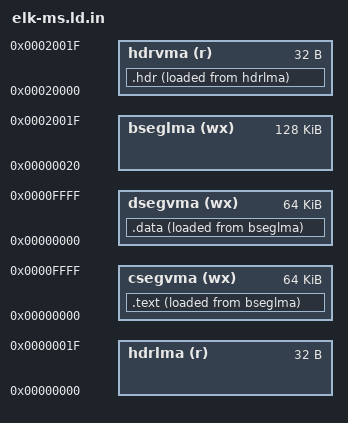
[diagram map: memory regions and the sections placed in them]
#!/bin/sh

set -e
cmd1='#'
cmd2='#'
w1=with
w2=with
case "$1" in
  -nostdlib)
    cmd1='/^@if_starts@/,/^@endif@/ d'
    cmd2='/^@if_libs@/,/^@endif@/ d'
    w1=without
    w2=without;;
  -nostartfiles)
     cmd1='/^@if_starts@/,/^@endif@/ d'
     w1=without;;
  -nodefaultlibs)
     cmd2='/^@if_libs@/,/^@endif@/ d'
     w2=without;;
esac
sed -e "$cmd1" -e "$cmd2" -e "s;@withstarts@;$w1;g" -e "s;@withlibs@;$w2;g" \
    -e "s/@self@/`basename "$0"`/g" -e "/^@if/ d" -e "/^@endif@/ d" <<'EOF'
/* Linker script for ELKS executables with separate data and text segments,
   @withstarts@ startup files, and @withlibs@ default libraries.  Generated
   from @self@.  */

OUTPUT_FORMAT(binary)
ENTRY(_start)
@if_starts@
INPUT(-l:crtbegin.o -l:crtend.o -l:elks-crt0.o)
@endif@
@if_libs@
GROUP(-lc -lgcc -lelks -lm)
@endif@
MEMORY
  {
    /* Place header VMA outside of program address space.  */
    hdrlma  (r)	 : ORIGIN = 0x00000, LENGTH = 32
    hdrvma  (r)  : ORIGIN = 0x20000, LENGTH = 32

    /* Account for the 32-byte header.  */
    bseglma (wx) : ORIGIN = 0x00020, LENGTH = 0x20000
    csegvma (wx) : ORIGIN = 0x00000, LENGTH = 0x10000
    dsegvma (wx) : ORIGIN = 0x00000, LENGTH = 0x10000
  }

SECTIONS
  {
    /* There's no binutils configuration which directly supports the ELKS
       binary format, but's it's easy to create the necessary header.  */
    .hdr : {
		LONG (0x04300301);	/* Magic.  */
		LONG (32);		/* Header length.  */
		LONG (__ltext_padded);
		LONG (__ldata);
		LONG (__lbss);
		LONG (_start);		/* Entry point.  */
		LONG (_total_adjusted);	/* Total memory allocated.  */
		LONG (0);
	} >hdrvma AT>hdrlma

    /* Target text sections.  */
    .text : {
		__stext = .;
		*(.startupA)
		*(.init)
		*(.startupB)
		*(.fini)
		*(.startupC)
		*(.text) *(.text.*)
		__etext = .;

		/* Work around linker bug.  The linker will 4-byte align the VMA
		 * without being asked to do so, but won't do the same for the
		 * LMA.  Result: VMA out of sync with LMA.
		 * GNU ld version 2.17.50.0.12-3 20070128  */
		. = ALIGN(4);
		__etext_padded = .;
	} >csegvma AT>bseglma
	__ltext = __etext - __stext;
	__ltext_padded = __etext_padded - __stext;

    /* Target data sections.  */
    .data : {
		__sdata = .;

		/* Build lists of constructors and destructors.  */
		KEEP (*crtbegin*.o(.ctors))
		KEEP (*(EXCLUDE_FILE (*crtend*.o ) .ctors))
		KEEP (*(SORT(.ctors.*)))
		KEEP (*(.ctors))

		KEEP (*crtbegin*.o(.dtors))
		KEEP (*(EXCLUDE_FILE (*crtend*.o ) .dtors))
		KEEP (*(SORT(.dtors.*)))
		KEEP (*(.dtors))

		*(.rodata) *(.rodata.*)
		*(.data) *(.data.*)
		__edata = .;

		__sbss = .;
		*(.bss) *(.bss.*)
		*(COMMON)
		__ebss = .;
		. = ALIGN (8);
		__ebss_padded = .;

		/* Minimum address allowed for sbrk() to use.  */
		__heap_end_minimum = .;
		ASSERT (. + 0x100 <= 0x10000,
		    "Error: too large for a small-model ELKS a.out file.");
		ASSERT (ABSOLUTE (DEFINED ("main!") ? "main!" : 0) == 0,
		    "Error: using non-segelf ld script with segelf program.");
		ASSERT (ABSOLUTE (DEFINED ("environ!") ? "environ!" : 0) == 0,
		    "Error: using non-segelf ld script with segelf library.");
	} >dsegvma AT>bseglma
	__ldata = __edata - __sdata;
	__lbss  = __ebss  - __sbss;

	PROVIDE (_total = 0);
	_total_adjusted = _total == 0 ? 0
			  : MIN (0x10000, MAX (. + 0x100, _total));

    /DISCARD/ : { *(*) }
  }
EOF
